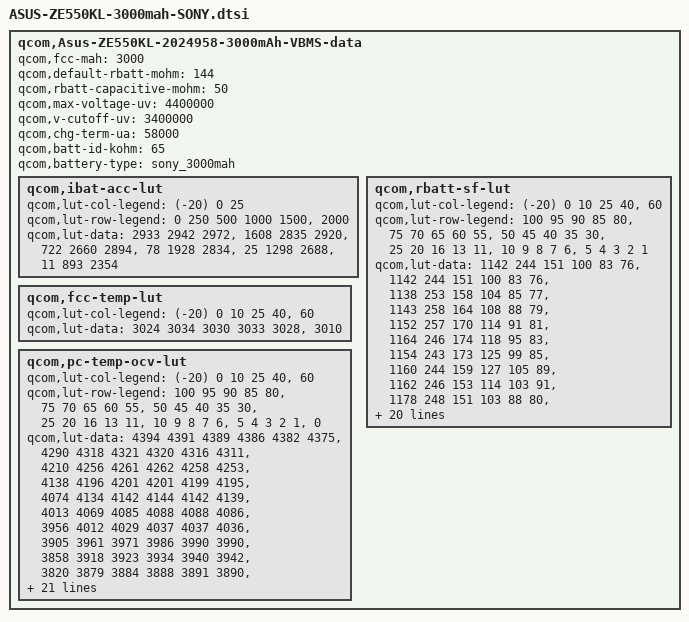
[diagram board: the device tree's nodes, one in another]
 qcom,Asus-ZE550KL-2024958-3000mAh-VBMS-data {
	qcom,fcc-mah = <3000>;
	qcom,default-rbatt-mohm = <144>;
	qcom,rbatt-capacitive-mohm = <50>;
	qcom,max-voltage-uv = <4400000>;
	qcom,v-cutoff-uv = <3400000>;
	qcom,chg-term-ua = <58000>;
	qcom,batt-id-kohm = <65>;
	qcom,battery-type = "sony_3000mah";

	qcom,ibat-acc-lut {
		qcom,lut-col-legend = <(-20) 0 25>;
		qcom,lut-row-legend = <0 250 500 1000 1500>,
				<2000>;
		qcom,lut-data = <2933 2942 2972>,
				<1608 2835 2920>,
				<722 2660 2894>,
				<78 1928 2834>,
				<25 1298 2688>,
				<11 893 2354>;
	};

	qcom,rbatt-sf-lut {
		qcom,lut-col-legend = <(-20) 0 10 25 40>,
				<60>;
		qcom,lut-row-legend = <100 95 90 85 80>,
				<75 70 65 60 55>,
				<50 45 40 35 30>,
				<25 20 16 13 11>,
				<10 9 8 7 6>,
				<5 4 3 2 1>;
		qcom,lut-data = <1142 244 151 100 83 76>,
				<1142 244 151 100 83 76>,
				<1138 253 158 104 85 77>,
				<1143 258 164 108 88 79>,
				<1152 257 170 114 91 81>,
				<1164 246 174 118 95 83>,
				<1154 243 173 125 99 85>,
				<1160 244 159 127 105 89>,
				<1162 246 153 114 103 91>,
				<1178 248 151 103 88 80>,
				<1210 252 154 103 85 78>,
				<1254 257 159 104 87 79>,
				<1312 265 162 108 90 81>,
				<1389 272 166 111 92 83>,
				<1496 279 169 112 92 82>,
				<1658 292 172 110 88 80>,
				<2033 301 173 109 88 81>,
				<2442 308 172 108 88 81>,
				<2875 323 169 107 88 79>,
				<2926 328 169 106 88 80>,
				<3192 342 175 108 89 81>,
				<3855 365 180 111 90 83>,
				<4907 404 190 113 92 85>,
				<6646 459 201 117 93 86>,
				<9793 548 214 118 92 84>,
				<15921 717 228 115 91 83>,
				<30178 1183 261 120 93 85>,
				<59299 2365 346 129 96 88>,
				<102571 4731 542 145 103 92>,
				<154333 9461 1083 189 121 115>;
	};

	qcom,fcc-temp-lut {
		qcom,lut-col-legend = <(-20) 0 10 25 40>,
				<60>;
		qcom,lut-data = <3024 3034 3030 3033 3028>,
				<3010>;
	};

	qcom,pc-temp-ocv-lut {
		qcom,lut-col-legend = <(-20) 0 10 25 40>,
				<60>;
		qcom,lut-row-legend = <100 95 90 85 80>,
				<75 70 65 60 55>,
				<50 45 40 35 30>,
				<25 20 16 13 11>,
				<10 9 8 7 6>,
				<5 4 3 2 1>,
				<0>;
		qcom,lut-data = <4394 4391 4389 4386 4382 4375>,
				<4290 4318 4321 4320 4316 4311>,
				<4210 4256 4261 4262 4258 4253>,
				<4138 4196 4201 4201 4199 4195>,
				<4074 4134 4142 4144 4142 4139>,
				<4013 4069 4085 4088 4088 4086>,
				<3956 4012 4029 4037 4037 4036>,
				<3905 3961 3971 3986 3990 3990>,
				<3858 3918 3923 3934 3940 3942>,
				<3820 3879 3884 3888 3891 3890>,
				<3790 3846 3852 3856 3858 3857>,
				<3768 3818 3826 3829 3831 3830>,
				<3746 3794 3802 3807 3809 3808>,
				<3728 3774 3782 3788 3790 3789>,
				<3710 3758 3766 3770 3769 3764>,
				<3692 3742 3750 3750 3744 3732>,
				<3672 3720 3728 3726 3721 3710>,
				<3654 3694 3703 3702 3697 3686>,
				<3635 3672 3680 3682 3677 3664>,
				<3622 3660 3668 3672 3668 3658>,
				<3612 3654 3662 3668 3665 3654>,
				<3600 3646 3656 3664 3661 3650>,
				<3585 3637 3650 3658 3656 3646>,
				<3565 3626 3640 3649 3646 3634>,
				<3541 3608 3622 3630 3625 3610>,
				<3507 3576 3588 3590 3586 3570>,
				<3457 3522 3535 3536 3534 3518>,
				<3387 3448 3466 3469 3467 3452>,
				<3290 3347 3374 3378 3379 3364>,
				<3164 3207 3244 3243 3248 3232>,
				<3000 3000 3000 3000 3000 3000>;
	};
};
